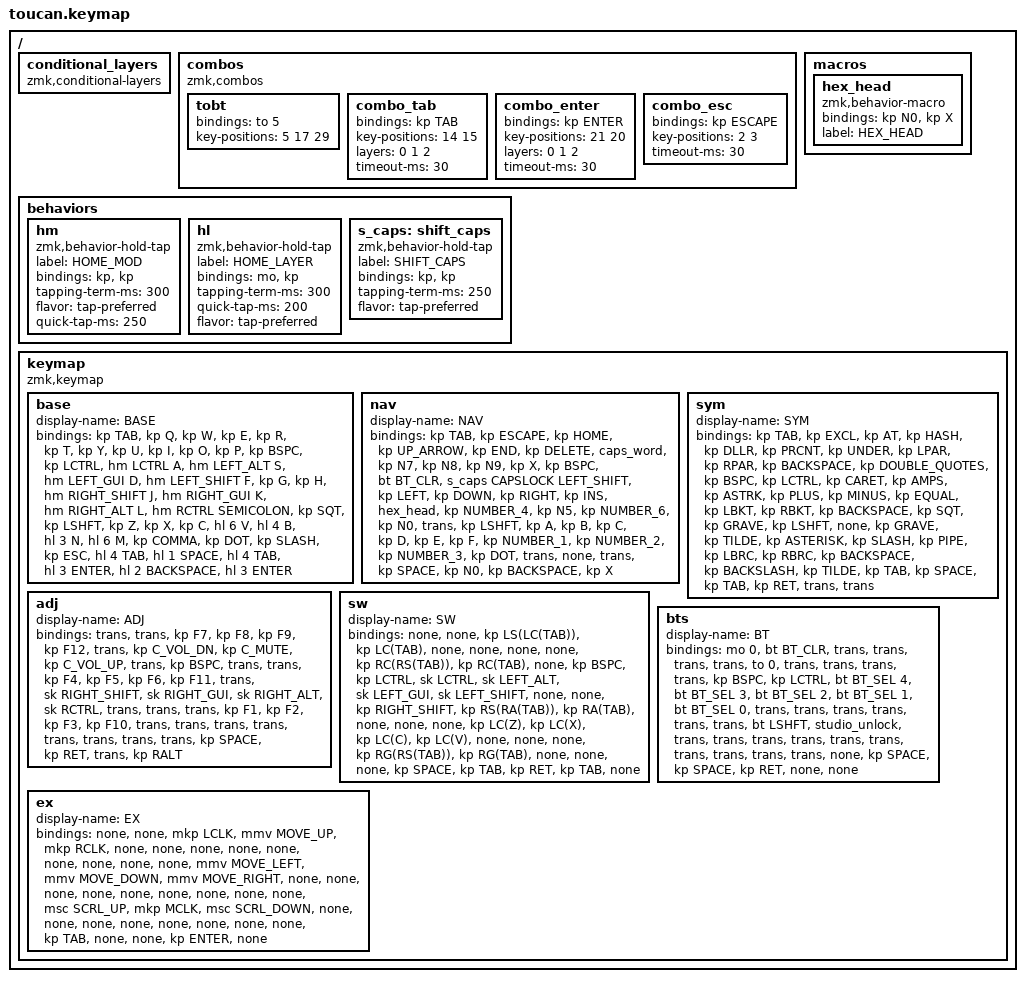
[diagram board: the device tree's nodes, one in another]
#include <behaviors.dtsi>
#include <dt-bindings/zmk/bt.h>
#include <dt-bindings/zmk/keys.h>
#include <dt-bindings/zmk/pointing.h>

#define BASE 0
#define NAV  1
#define SYM  2
#define ADJ  3
#define SW   4
#define BTS  5
#define EX   6

/ {
    conditional_layers { compatible = "zmk,conditional-layers"; };

    combos {
        compatible = "zmk,combos";

        tobt {
            bindings = <&to 5>;
            key-positions = <5 17 29>;
        };

        combo_tab {
            bindings = <&kp TAB>;
            key-positions = <14 15>;
            layers = <0 1 2>;
            timeout-ms = <30>;
        };

        combo_enter {
            bindings = <&kp ENTER>;
            key-positions = <21 20>;
            layers = <0 1 2>;
            timeout-ms = <30>;
        };

        combo_esc {
            bindings = <&kp ESCAPE>;
            key-positions = <2 3>;
            timeout-ms = <30>;
        };
    };

    behaviors {
        hm: hm {
            compatible = "zmk,behavior-hold-tap";
            label = "HOME_MOD";
            bindings = <&kp>, <&kp>;

            #binding-cells = <2>;
            tapping-term-ms = <300>;
            flavor = "tap-preferred";
            quick-tap-ms = <250>;
        };

        hl: hl {
            compatible = "zmk,behavior-hold-tap";
            label = "HOME_LAYER";
            bindings = <&mo>, <&kp>;

            #binding-cells = <2>;
            tapping-term-ms = <300>;
            quick-tap-ms = <200>;
            flavor = "tap-preferred";
        };

        s_caps: shift_caps {
            compatible = "zmk,behavior-hold-tap";
            label = "SHIFT_CAPS";
            bindings = <&kp>, <&kp>;

            #binding-cells = <2>;
            tapping-term-ms = <250>;
            flavor = "tap-preferred";
        };
    };

    macros {
        hex_head: hex_head {
            compatible = "zmk,behavior-macro";
            #binding-cells = <0>;
            bindings = <&kp N0 &kp X>;
            label = "HEX_HEAD";
        };
    };

    keymap {
        compatible = "zmk,keymap";

        base {
            display-name = "BASE";
            bindings = <
&kp TAB  &kp Q  &kp W  &kp E  &kp R  &kp T  &kp Y  &kp U  &kp I  &kp O  &kp P  &kp BSPC  &kp LCTRL  &hm LCTRL A  &hm LEFT_ALT S  &hm LEFT_GUI D  &hm LEFT_SHIFT F  &kp G  &kp H  &hm RIGHT_SHIFT J  &hm RIGHT_GUI K  &hm RIGHT_ALT L  &hm RCTRL SEMICOLON  &kp SQT  &kp LSHFT  &kp Z  &kp X  &kp C  &hl 6 V  &hl 4 B  &hl 3 N  &hl 6 M  &kp COMMA  &kp DOT  &kp SLASH  &kp ESC  &hl 4 TAB  &hl 1 SPACE  &hl 4 TAB  &hl 3 ENTER  &hl 2 BACKSPACE  &hl 3 ENTER
            >;
        };

        nav {
            display-name = "NAV";
            bindings = <
&kp TAB  &kp ESCAPE  &kp HOME  &kp UP_ARROW  &kp END  &kp DELETE  &caps_word  &kp N7  &kp N8  &kp N9  &kp X  &kp BSPC  &bt BT_CLR  &s_caps CAPSLOCK LEFT_SHIFT  &kp LEFT  &kp DOWN  &kp RIGHT  &kp INS  &hex_head  &kp NUMBER_4  &kp N5  &kp NUMBER_6  &kp N0  &trans  &kp LSHFT  &kp A  &kp B  &kp C  &kp D  &kp E  &kp F  &kp NUMBER_1  &kp NUMBER_2  &kp NUMBER_3  &kp DOT  &trans  &none  &trans  &kp SPACE  &kp N0  &kp BACKSPACE  &kp X
            >;
        };

        sym {
            display-name = "SYM";
            bindings = <
&kp TAB  &kp EXCL  &kp AT  &kp HASH  &kp DLLR  &kp PRCNT  &kp UNDER  &kp LPAR  &kp RPAR  &kp BACKSPACE  &kp DOUBLE_QUOTES  &kp BSPC  &kp LCTRL  &kp CARET  &kp AMPS  &kp ASTRK  &kp PLUS  &kp MINUS  &kp EQUAL  &kp LBKT  &kp RBKT  &kp BACKSPACE  &kp SQT  &kp GRAVE  &kp LSHFT  &none  &kp GRAVE  &kp TILDE  &kp ASTERISK  &kp SLASH  &kp PIPE  &kp LBRC  &kp RBRC  &kp BACKSPACE  &kp BACKSLASH  &kp TILDE  &kp TAB  &kp SPACE  &kp TAB  &kp RET  &trans  &trans
            >;
        };

        adj {
            display-name = "ADJ";
            bindings = <
&trans  &trans  &kp F7  &kp F8  &kp F9  &kp F12  &trans  &kp C_VOL_DN  &kp C_MUTE  &kp C_VOL_UP  &trans  &kp BSPC  &trans  &trans  &kp F4  &kp F5  &kp F6  &kp F11  &trans  &sk RIGHT_SHIFT  &sk RIGHT_GUI  &sk RIGHT_ALT  &sk RCTRL  &trans  &trans  &trans  &kp F1  &kp F2  &kp F3  &kp F10  &trans  &trans  &trans  &trans  &trans  &trans  &trans  &trans  &kp SPACE  &kp RET  &trans  &kp RALT
            >;
        };

        sw {
            display-name = "SW";
            bindings = <
&none  &none  &kp LS(LC(TAB))  &kp LC(TAB)  &none  &none  &none  &none  &kp RC(RS(TAB))  &kp RC(TAB)  &none  &kp BSPC  &kp LCTRL  &sk LCTRL  &sk LEFT_ALT  &sk LEFT_GUI  &sk LEFT_SHIFT  &none  &none  &kp RIGHT_SHIFT  &kp RS(RA(TAB))  &kp RA(TAB)  &none  &none  &none  &kp LC(Z)  &kp LC(X)  &kp LC(C)  &kp LC(V)  &none  &none  &none  &kp RG(RS(TAB))  &kp RG(TAB)  &none  &none  &none  &kp SPACE  &kp TAB  &kp RET  &kp TAB  &none
            >;
        };

        bts {
            display-name = "BT";
            bindings = <
&mo 0  &bt BT_CLR  &trans  &trans  &trans  &trans  &to 0  &trans  &trans  &trans  &trans  &kp BSPC  &kp LCTRL  &bt BT_SEL 4  &bt BT_SEL 3  &bt BT_SEL 2  &bt BT_SEL 1  &bt BT_SEL 0  &trans  &trans  &trans  &trans  &trans  &trans  &bt LSHFT  &studio_unlock  &trans  &trans  &trans  &trans  &trans  &trans  &trans  &trans  &trans  &trans  &none  &kp SPACE  &kp SPACE  &kp RET  &none  &none
            >;
        };

        ex {
            display-name = "EX";
            bindings = <
&none  &none  &mkp LCLK  &mmv MOVE_UP  &mkp RCLK  &none  &none  &none  &none  &none  &none  &none  &none  &none  &mmv MOVE_LEFT  &mmv MOVE_DOWN  &mmv MOVE_RIGHT  &none  &none  &none  &none  &none  &none  &none  &none  &none  &msc SCRL_UP  &mkp MCLK  &msc SCRL_DOWN  &none  &none  &none  &none  &none  &none  &none  &none  &kp TAB  &none  &none  &kp ENTER  &none
            >;
        };
    };
};
